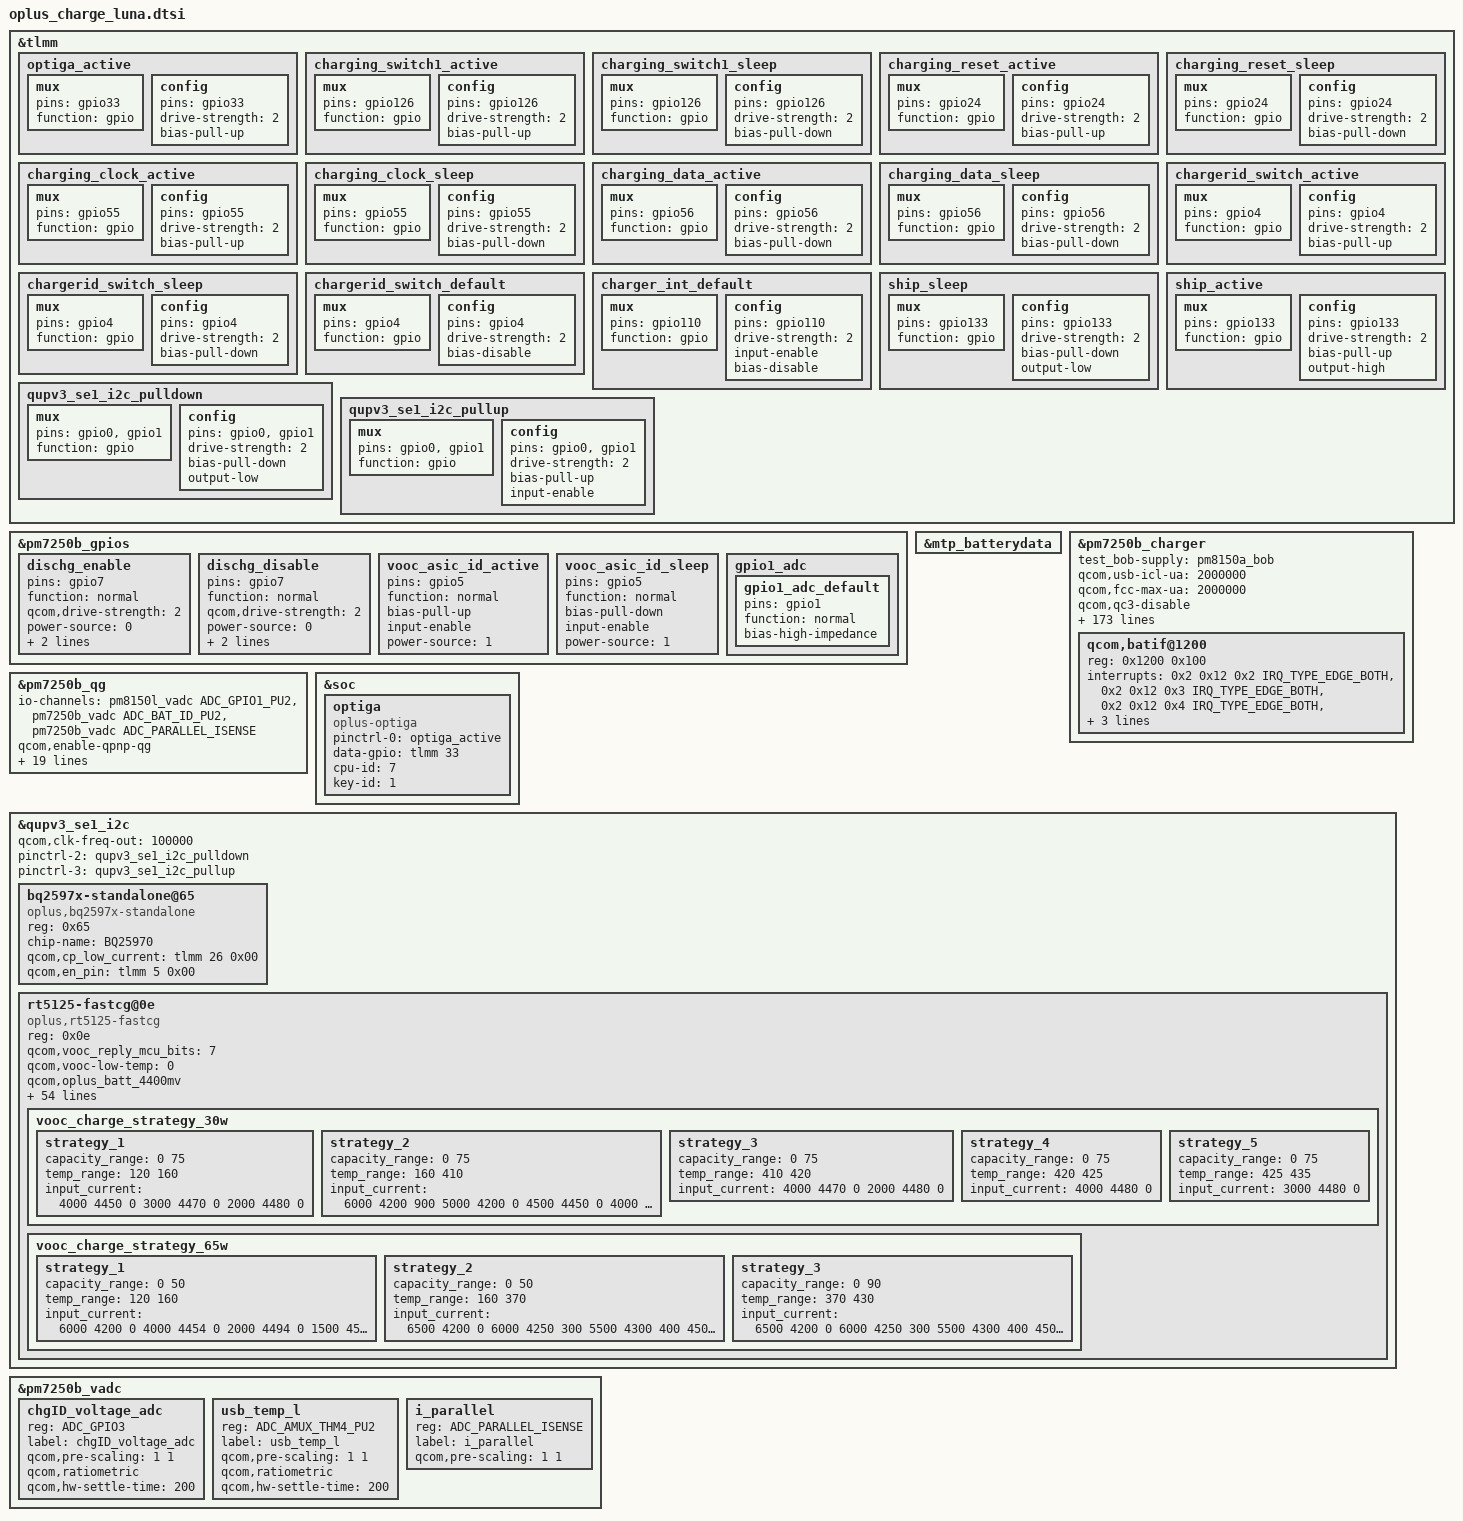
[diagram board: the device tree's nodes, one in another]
// SPDX-License-Identifier: GPL-2.0-only
/*
 * Copyright (C) 2018-2020 Oplus. All rights reserved.
 */

&tlmm {
	optiga_active: optiga_active {
				mux {
					pins = "gpio33";
					function = "gpio";
				};

				config {
					pins = "gpio33";
					drive-strength = <2>;
					bias-pull-up;
				};
	};

			charging_switch1_active: charging_switch1_active {
				mux {
					pins = "gpio126";
					function = "gpio";
				};

				config {
					pins = "gpio126";
					drive-strength = <2>;
					bias-pull-up;
				};
			};

			charging_switch1_sleep: charging_switch1_sleep {
				mux {
					pins = "gpio126";
					function = "gpio";
				};

				config {
					pins = "gpio126";
					drive-strength = <2>;
					bias-pull-down;
				};
			};

			charging_reset_active: charging_reset_active {
				mux {
					pins = "gpio24";
					function = "gpio";
				};

				config {
					pins = "gpio24";
					drive-strength = <2>;
					bias-pull-up;
				};
			};

			charging_reset_sleep: charging_reset_sleep {
				mux {
					pins = "gpio24";
					function = "gpio";
				};

				config {
					pins = "gpio24";
					drive-strength = <2>;
					bias-pull-down;
				};
			};

			charging_clock_active: charging_clock_active {
				mux {
					pins = "gpio55";
					function = "gpio";
				};

				config {
					pins = "gpio55";
					drive-strength = <2>;
					bias-pull-up;
				};
			};

			charging_clock_sleep: charging_clock_sleep {
				mux {
					pins = "gpio55";
					function = "gpio";
				};

				config {
					pins = "gpio55";
					drive-strength = <2>;
					bias-pull-down;
				};
			};

			charging_data_active: charging_data_active {
				mux {
					pins = "gpio56";
					function = "gpio";
				};

				config {
					pins = "gpio56";
					drive-strength = <2>;
					bias-pull-down;
				};
			};

			charging_data_sleep: charging_data_sleep {
				mux {
					pins = "gpio56";
					function = "gpio";
				};

				config {
					pins = "gpio56";
					drive-strength = <2>;
					bias-pull-down;
				};
			};

			chargerid_switch_active: chargerid_switch_active {
				mux {
					pins = "gpio4";
					function = "gpio";
				};

				config {
					pins = "gpio4";
					drive-strength = <2>;
					bias-pull-up;
				};
			};

			chargerid_switch_sleep: chargerid_switch_sleep {
				mux {
					pins = "gpio4";
					function = "gpio";
				};

				config {
					pins = "gpio4";
					drive-strength = <2>;
					bias-pull-down;
				};
			};

			chargerid_switch_default: chargerid_switch_default {
				mux {
					pins = "gpio4";
					function = "gpio";
				};

				config {
					pins = "gpio4";
					drive-strength = <2>;
					bias-disable; /* NO PULL */
				};
			};

			charger_int_default: charger_int_default {
				mux {
					pins = "gpio110";
					function = "gpio";
				};

				config {
					pins = "gpio110";
					drive-strength = <2>;
					input-enable;
					//bias-pull-up; /*PULL UP*/
					bias-disable;
				};
			};

			ship_sleep: ship_sleep {
				mux {
					pins = "gpio133";
					function = "gpio";
				};

				config {
					pins = "gpio133";
					drive-strength = <2>;
					bias-pull-down;
					output-low;
				};
			};

			ship_active: ship_active {
				mux {
					pins = "gpio133";
					function = "gpio";
				};

				config {
					pins = "gpio133";
					drive-strength = <2>;
					bias-pull-up;
					output-high;
				};
			};

			qupv3_se1_i2c_pulldown: qupv3_se1_i2c_pulldown {
				mux {
					pins = "gpio0", "gpio1";
					function = "gpio";
				};

				config {
					pins = "gpio0", "gpio1";
					drive-strength = <2>;
					bias-pull-down;
					output-low;
				};
			};

			qupv3_se1_i2c_pullup: qupv3_se1_i2c_pullup {
				mux {
					pins = "gpio0", "gpio1";
					function = "gpio";
				};

				config {
					pins = "gpio0", "gpio1";
					drive-strength = <2>;
					bias-pull-up;
					input-enable;
				};
			};

/*
			chg_qupv3_se2_2uart_default: chg_qupv3_se2_2uart_default {
				mux {
					pins = "gpio36", "gpio37";
					function = "gpio";
				};

				config {
					pins = "gpio36", "gpio37";
					drive-strength = <2>;
					input-enable;
					bias-pull-down;
				};
			};

			chg_qupv3_se2_2uart_sleep: chg_qupv3_se2_2uart_sleep {
				mux {
					pins = "gpio36", "gpio37";
					function = "gpio";
				};

				config {
					pins = "gpio36", "gpio37";
					drive-strength = <2>;
					input-enable;
					bias-disable;
				};
			};

			shipmode_id_active: shipmode_id_active {
				mux {
					pins = "gpio25";
					function = "gpio";
				};

				config {
					pins = "gpio25";
					drive-strength = <2>;
					input-enable;
					bias-pull-up; 
				};
			};

			shortc_active: shortc_active {
				mux {
					pins = "gpio43";
					function = "gpio";
				};

				config {
					pins = "gpio43";
					drive-strength = <2>;
					input-enable;
					bias-pull-up; 
				};
			};
*/

};

&pm7250b_gpios {
	dischg_enable: dischg_enable{
		pins = "gpio7";
		function = "normal";
		qcom,drive-strength = <2>;
		power-source = <0>;
		bias-disable;
		output-high;
	};

	dischg_disable: dischg_disable{
		pins = "gpio7";
		function = "normal";
		qcom,drive-strength = <2>;
		power-source = <0>;
		bias-disable;
		output-low;
	};

    vooc_asic_id_active: vooc_asic_id_active {
		pins = "gpio5";
		function = "normal";
		bias-pull-up;
		input-enable;
		power-source = <1>;
	};

    vooc_asic_id_sleep: vooc_asic_id_sleep {
		pins = "gpio5";
		function = "normal";
		bias-pull-down;
		input-enable;
		power-source = <1>;
	};

	gpio1_adc {
        gpio1_adc_default: gpio1_adc_default {
        pins = "gpio1"; /* GPIO 1 */
        function = "normal"; /* normal */
        bias-high-impedance; /* DISABLE GPIO1 for ADC*/
        };
    };
};

&mtp_batterydata {
	#include "oplus_battery_4500mah_100k_pm7250b_BLP857.dtsi"
	/delete-node/ qcom,ATL466271_3300mAh;
	/delete-node/ qcom,alium_860_89032_0000_3600mAh;
};

&pm7250b_charger {
			test_bob-supply = <&pm8150a_bob>;
			qcom,usb-icl-ua = <2000000>;
			qcom,fcc-max-ua = <2000000>;
			//qcom,fv-max-uv = <4373000>;
			qcom,qc3-disable;
			qcom,hvdcp-disable;
			qcom,get_mcu_voltage_enable;
			qcom,smart_charging_screenoff;
			qcom,internal_gauge_with_asic = <1>;
			//io-channels = <&pm8150b_vadc ADC_GPIO3>;
			//io-channel-names = "chgID_voltage_adc";
			qcom,otg-cl-ua = <1400000>;
			qcom,float-option = <1>;
			qcom,oplus-pps-usbpd-detection = <&pm7250b_pdphy>;

			qcom,usbtemp_batttemp_gap = <12>;

			//for oplus chg framework:
			qcom,input_current_charger_ma = <2000>;
			qcom,pd_input_current_charger_ma = <2000>;
			qcom,qc_input_current_charger_ma = <2000>;
			qcom,input_current_usb_ma = <500>;

			qcom,input_current_led_ma = <1200>;
			qcom,input_current_led_ma_high = <1200>;
			qcom,input_current_led_ma_warm = <1500>;
			qcom,input_current_led_ma_normal = <2000>;

			qcom,input_current_camera_ma = <1200>;
			qcom,input_current_cdp_ma = <1600>;
			//qcom,input_current_led_ma_overtemp = <900>;
			qcom,overtemp_bat_decidegc = <350>;
			qcom,iterm_disabled = <0>;
			sw_full_count = <25>;
			qcom,iterm_ma = <221>;
			qcom,recharge-mv = <100>;
			qcom,batt_capacity_mah = <4500>;/*typical capacity*/
			//qcom,batt_capacity_mah = <3920>; /*rated capacity*/

			qcom,removed_bat_decidegc = <190>;  /*<-19C*/

			qcom,cold_bat_decidegc = <20>;  /*-2C~0C*/
			qcom,temp_cold_vfloat_mv = <3980>;
			qcom,temp_cold_fastchg_current_ma = <314>;

			qcom,little_cold_bat_decidegc = <0>;	/*0C~5C*/
			qcom,temp_little_cold_vfloat_mv = <4435>;
			qcom,temp_little_cold_fastchg_current_ma_high = <2200>;
			qcom,temp_little_cold_fastchg_current_ma_low = <2200>;
			qcom,pd_temp_little_cold_fastchg_current_ma_high = <2594>;
			qcom,pd_temp_little_cold_fastchg_current_ma_low = <3300>;
			qcom,temp_little_cold_fastchg_current_ma = <1076>;
			qcom,qc_temp_little_cold_fastchg_current_ma_high = <2594>;
			qcom,qc_temp_little_cold_fastchg_current_ma_low = <3300>;
        
			qcom,cool_bat_decidegc = <50>;	/*5C~12C*/
			qcom,temp_cool_vfloat_mv = <4435>;
			qcom,temp_cool_fastchg_current_ma_high = <2200>;
			qcom,temp_cool_fastchg_current_ma_low = <2200>;
			qcom,qc_temp_cool_fastchg_current_ma_high = <3300>;	//2464
			qcom,qc_temp_cool_fastchg_current_ma_low = <3300>;	//1760
			qcom,pd_temp_cool_fastchg_current_ma_high = <3300>;	//2464
			qcom,pd_temp_cool_fastchg_current_ma_low = <3300>;	//1760

			qcom,little_cool_bat_decidegc = <120>;	/*12C~16C*/
			qcom,temp_little_cool_vfloat_mv = <4435>;
			qcom,temp_little_cool_fastchg_current_ma = <2200>;
			qcom,pd_temp_little_cool_fastchg_current_ma = <3300>;
			qcom,qc_temp_little_cool_fastchg_current_ma = <3300>;
	
			qcom,normal_bat_decidegc = <160>;	/*16C~44C*/
			qcom,temp_normal_fastchg_current_ma = <2200>;
			qcom,pd_temp_normal_fastchg_current_ma = <3300>;
			qcom,qc_temp_normal_fastchg_current_ma = <3300>;
			qcom,temp_normal_vfloat_mv = <4435>;

			qcom,warm_bat_decidegc = <450>;		/*45C~53C*/ /*8pin Bat Vooc project need add 3 degree C*/
			qcom,temp_warm_vfloat_mv = <4130>;
			qcom,temp_warm_fastchg_current_ma = <1152>;
			qcom,pd_temp_warm_fastchg_current_ma = <1152>;
			qcom,qc_temp_warm_fastchg_current_ma = <1152>;
			qcom,temp_warm_fastchg_current_ma_led_on = <500>;
	
			qcom,hot_bat_decidegc = <530>;

			qcom,non_standard_vfloat_mv = <3980>;
			qcom,non_standard_fastchg_current_ma = <550>;
	
			qcom,short_c_bat_cv_mv = <4330>;
			qcom,short_c_bat_vfloat_mv = <3800>;
			qcom,short_c_bat_fastchg_current_ma = <512>;

			qcom,cold_vfloat_sw_limit = <3930>;
			qcom,little_cold_vfloat_sw_limit = <4370>;
			qcom,cool_vfloat_sw_limit = <4370>;
			qcom,little_cool_vfloat_sw_limit = <4370>;
			qcom,normal_vfloat_sw_limit = <4435>;
			qcom,warm_vfloat_sw_limit = <4080>;
			qcom,non_standard_vfloat_sw_limit = <3930>;
			qcom,short_c_bat_vfloat_sw_limit = <3750>;

			qcom,max_chg_time_sec = <36000>;
			qcom,charger_hv_thr = <11000>;
			qcom,charger_recv_thr = <9700>;
			qcom,charger_lv_thr = <3400>;
			qcom,vbatt_full_thr = <4400>;
			qcom,vbatt_hv_thr = <4600>;
			qcom,vfloat_step_mv = <16>;
			qcom,non_standard_vfloat_over_sw_limit = <3980>;
			qcom,cold_vfloat_over_sw_limit = <3980>;
			qcom,little_cold_vfloat_over_sw_limit = <4440>;
			qcom,cool_vfloat_over_sw_limit = <4440>;
			qcom,little_cool_vfloat_over_sw_limit = <4440>;
			qcom,normal_vfloat_over_sw_limit = <4440>;
			qcom,warm_vfloat_over_sw_limit = <4130>;

			qcom,vbatt_power_off = <3300>;
			qcom,vbatt_soc_1 = <3410>;
			qcom,vooc_project = <3>;
			qcom,vbatt_num = <1>;
			qcom,new_ui_warning_support;
			qcom,ffc_support;
			recharge_after_full;
                        qcom,nightstandby_support;
                        qcom,vooc_enable_charger_first;

			qcom,normal_vterm_hw_inc = <18>;
			qcom,non_normal_vterm_hw_inc = <18>;

			qcom,ff1_normal_fastchg_ma = <1500>;
			qcom,ff1_warm_fastchg_ma = <1750>;	/* 35C ~ 40c */
			qcom,ff1_exit_step_ma = <100>;
			qcom,ff1_warm_exit_step_ma = <150>;
			qcom,ffc2_normal_fastchg_ma = <1500>;/*12C~35c*/
			qcom,ffc2_warm_fastchg_ma = <1750>;	/* 35C ~ 40c */
			qcom,ffc2_temp_warm_decidegc = <350>;
			qcom,ffc2_temp_high_decidegc = <400>;
			qcom,ffc2_temp_low_decidegc = <160>;
			qcom,ffc2_exit_step_ma = <150>;
			qcom,ffc2_warm_exit_step_ma = <150>;

			qcom,ffc_normal_vfloat_sw_limit = <4485>;
			qcom,ffc2_normal_vfloat_sw_limit = <4485>;
			qcom,ffc_temp_normal_vfloat_mv = <4550>;
			qcom,ffc_normal_vfloat_over_sw_limit = <4550>;

			qcom,default_iterm_ma = <221>;
			qcom,default_temp_normal_fastchg_current_ma = <2200>;
			qcom,default_normal_vfloat_sw_limit = <4385>;
			qcom,default_temp_normal_vfloat_mv = <4435>;
			qcom,default_normal_vfloat_over_sw_limit = <4440>;

			qcom,default_temp_little_cool_fastchg_current_ma = <2200>;
			qcom,default_little_cool_vfloat_sw_limit = <4385>;
			qcom,default_temp_little_cool_vfloat_mv = <4435>;
			qcom,default_little_cool_vfloat_over_sw_limit = <4445>;
			qcom,vbatt_pdqc_to_5v_thr = <4500>;
			qcom,vbatt_pdqc_to_9v_thr = <4500>;
			qcom,smart_charge_version = <1>;

			qcom,vooc_show_ui_soc_decimal;
			qcom,usbtemp_batttemp_high_gap = <14>;
			qcom,ui_soc_decimal_speedmin = <20>;//2A

			///qcom,offset_temp = <30>;
			//for control:
			//qcom,suspend_after_full;
			qcom,check_batt_full_by_sw;
			//qcom,external_gauge;
                        qcom,external_authenticate;
			qcom,fg_bcl_poll_enable;
			qcom,chg_ctrl_by_lcd;
			qcom,chg_ctrl_by_camera;
			qcom,sw_vfloat_over_protect_enable;
			qcom,lpd-disable;
			//qcom,smooth_switch;
			qcom,dual_ffc;

			qcom,chargerid_switch-gpio = <&tlmm 4 0x00>;
			qcom,ship-mode-config = <1>;
			qcom,ship-gpio = <&tlmm 133 0x00>;
			//qcom,shortc-gpio = <&tlmm 43 0x00>;
			qcom,dischg-gpio = <&pm7250b_gpios 7 0x00>;

			io-channels = <&pm7250b_vadc ADC_USB_IN_V_16>,
							<&pm7250b_vadc ADC_USB_IN_I>,
							<&pm7250b_vadc ADC_CHG_TEMP>,
							<&pm7250b_vadc ADC_GPIO3>,
							<&pm7250b_vadc ADC_AMUX_THM4_PU2>,
//
							<&pm7250b_vadc ADC_DIE_TEMP>,
							<&pm7250b_vadc ADC_AMUX_THM3_PU2>,
							<&pm7250b_vadc ADC_SBUx>,
							<&pm7250b_vadc ADC_VPH_PWR>,
							<&pm8150l_vadc ADC_AMUX_THM2_PU2>;
			io-channel-names = "usb_in_voltage",
								"usb_in_current",
								"chg_temp",
								"chgID_voltage_adc",
								"usb_temp_l",
//
								"die_temp",
								"usb_temp_r",
//#else
								//"conn_temp",
//#endif
								"sbux_res",
								"vph_voltage",
								"skin_temp";

			pinctrl-names = "chargerid_switch_active", "chargerid_switch_sleep", "chargerid_switch_default",
							"ship_active", "ship_sleep",
							"dischg_enable", "dischg_disable",
							"gpio1_adc_default";

			pinctrl-0 = <&chargerid_switch_active>;
			pinctrl-1 = <&chargerid_switch_sleep>;
			pinctrl-2 = <&chargerid_switch_default>;
			pinctrl-3 = <&ship_active>;
			pinctrl-4 = <&ship_sleep>;
			pinctrl-5 = <&dischg_enable>;
			pinctrl-6 = <&dischg_disable>;
			pinctrl-7 = <&gpio1_adc_default>;
};

&pm7250b_qg {
	status = "ok";
	io-channels = <&pm8150l_vadc ADC_GPIO1_PU2>,
		      <&pm7250b_vadc ADC_BAT_ID_PU2>,
			  <&pm7250b_vadc ADC_PARALLEL_ISENSE>;
	io-channel-names = "batt-therm_30k",
			   "batt-id",
			   "parallel_isense";
	qcom,enable-qpnp-qg;
	qcom,qg-ext-sns;
	qcom,oplus_small_board_temp;
	qcom,battery-data = <&mtp_batterydata>;
	qcom,qg-iterm-ma = <260>;
	qcom,rbat-conn-mohm = <0>;
	qcom,qg-fast-chg-config;
	//qcom,hold-soc-while-full;
	qcom,linearize-soc;
	qcom,cl-feedback-on;
	qcom,tcss-enable;
	qcom,fvss-enable;
	qcom,fvss-vbatt-mv = <3300>;
	qcom,bass-enable;
	qcom,s3-entry-ibat-ua = <40000>;
	qcom,s3-exit-ibat-ua = <40000>;
	qcom,adc-compensation-enable;
	qcom,compensation-impedance = <11>;
        qcom,asic-with-internal-gauge;
        qcom,ignore-shutdown-soc-secs = <86400>;
        qcom,shutdown-temp-diff = <250>;
};

&soc {
	optiga {
		compatible = "oplus-optiga";
		status = "ok";
		pinctrl-names = "optiga_active";
		pinctrl-0 = <&optiga_active>;
		data-gpio = <&tlmm 33 0x00>;
		cpu-id = <7>;
		key-id = <1>;
	};
};

&qupv3_se1_i2c {
	status = "okay";

	qcom,clk-freq-out = <100000>;
	pinctrl-names = "default", "sleep", "pulldown", "pullup";
	pinctrl-2 = <&qupv3_se1_i2c_pulldown>;
	pinctrl-3 = <&qupv3_se1_i2c_pullup>;
//#endif //OPLUS_FEATURE_CHG_BASIC
/*
	oplus_short-ic@58 {
		status = "okay";
		compatible = "oplus,oplus_short-ic";
		reg = <0x58>;
	};
*/
	bq2597x-standalone@65 {
		status = "okay";
		compatible = "oplus,bq2597x-standalone";
		reg = <0x65>;
		chip-name = "BQ25970";
		qcom,cp_low_current = <&tlmm 26 0x00>;
		qcom,en_pin = <&tlmm 5 0x00>;
	};
	
	rt5125-fastcg@0e{
		status = "okay";
		compatible = "oplus,rt5125-fastcg";
		reg = <0x0e>;
		qcom,vooc_reply_mcu_bits = <7>;
		qcom,vooc-low-temp = <0>;
		qcom,oplus_batt_4400mv;
		qcom,vooc-high-soc = <90>;
		qcom,vooc-high-temp = <430>;
		qcom,vooc_batt_over_high_temp = <440>;

		qcom,vooc_cool_bat_volt = <3650>;
		qcom,vooc_little_cool_bat_volt = <3550>;
		qcom,vooc_normal_bat_volt = <3450>;
		qcom,vooc_warm_bat_volt = <3350>;

		qcom,vooc_cool_bat_suspend_volt = <3650>;
		qcom,vooc_little_cool_bat_suspend_volt = <3550>;
		qcom,vooc_normal_bat_suspend_volt = <3450>;
		qcom,vooc_warm_bat_suspend_volt = <3350>;

		qcom,vooc_fw_update_newmethod;
		qcom,vooc-fw-type = <8>;
                #include "fastchg_fw/fw_svooc_10v5a5v6a_4.45v_2065c_rt5125_0x0020_4_3A.dtsi"
		qcom,support-single-batt-svooc;
		qcom,vooc_is_platform_gauge;
		qcom,vooc_multistep_adjust_current_support;
		qcom,vooc_multistep_initial_batt_temp = <1000>;
		qcom,vooc_strategy_normal_current = <0xb>;

		qcom,vooc_strategy1_batt_high_temp0 = <385>;
		qcom,vooc_strategy1_batt_high_temp1 = <395>;
		qcom,vooc_strategy1_batt_high_temp2 = <420>;
		qcom,vooc_strategy1_batt_low_temp2 = <410>;
		qcom,vooc_strategy1_batt_low_temp1 = <385>;
		qcom,vooc_strategy1_batt_low_temp0 = <375>;

		qcom,vooc_strategy1_high_current0 = <0x09>;
		qcom,vooc_strategy1_high_current1 = <0x07>;
		qcom,vooc_strategy1_high_current2 = <0x05>;
		qcom,vooc_strategy1_low_current2 = <0x07>;
		qcom,vooc_strategy1_low_current1 = <0x09>;
		qcom,vooc_strategy1_low_current0 = <0xb>;
/*
		qcom,vooc_strategy1_batt_high_temp0 = <710>;
		qcom,vooc_strategy1_batt_high_temp1 = <720>;
		qcom,vooc_strategy1_batt_high_temp2 = <735>;
		qcom,vooc_strategy1_batt_low_temp2 = <715>;
		qcom,vooc_strategy1_batt_low_temp1 = <700>;
		qcom,vooc_strategy1_batt_low_temp0 = <690>;

		qcom,vooc_strategy1_high_current0 = <0x03>;
		qcom,vooc_strategy1_high_current1 = <0x02>;
		qcom,vooc_strategy1_high_current2 = <0x02>;
		qcom,vooc_strategy1_low_current2 = <0x02>;
		qcom,vooc_strategy1_low_current1 = <0x02>;
		qcom,vooc_strategy1_low_current0 = <0x03>;
*/
		qcom,vooc_current_lvl = <2000
									2000
									2000
									3000
									4000
									5000
									6000
									7000
									8000
									9000
									10000>;

		pinctrl-names = "switch1_act_switch2_act", "switch1_sleep_switch2_sleep",
						"switch1_act_switch3_act", "switch1_sleep_switch3_sleep",
						"switch1_act_switch2_sleep", "switch1_sleep_switch2_act",
						"clock_active","clock_sleep",
						"data_active","data_sleep",
						"reset_active","reset_sleep",
						"vooc_asic_id_active","vooc_asic_id_sleep";
		pinctrl-0 = <&charging_switch1_active>;
		pinctrl-1 = <&charging_switch1_sleep>;
		pinctrl-2 = <&charging_switch1_active>;
		pinctrl-3 = <&charging_switch1_sleep>;
		pinctrl-4 = <&charging_switch1_active>;
		pinctrl-5 = <&charging_switch1_sleep>;
		pinctrl-6 = <&charging_clock_active>;
		pinctrl-7 = <&charging_clock_sleep>;
		pinctrl-8 = <&charging_data_active>;
		pinctrl-9 = <&charging_data_sleep>;
		pinctrl-10 = <&charging_reset_active>;
		pinctrl-11 = <&charging_reset_sleep>;
		pinctrl-12 = <&vooc_asic_id_active>;
		pinctrl-13 = <&vooc_asic_id_sleep>;

		qcom,charging_switch1-gpio = <&tlmm 126 0x00>;
		qcom,charging_switch1_ctr1-gpio 	= <&tlmm 132 0x00>;
		//qcom,charging_switch2-gpio 		= <&tlmm 113 0x00>;
		//qcom,charging_switch3-gpio 		= <&tlmm 38 0x00>;

		qcom,charging_reset-gpio 			= <&tlmm 24 0x00>;
		qcom,charging_clock-gpio 			= <&tlmm 55 0x00>;
		qcom,charging_data-gpio 			= <&tlmm 56 0x00>;
		qcom,vooc_asic_id-gpio				= <&pm7250b_gpios 5 0x00>;

                qcom,vooc-max-input-volt-support = <10000>;     //10V
                qcom,vooc-max-input-current-support = <6500>;   //6A
                vooc_charge_strategy_30w {
                        strategy_1 {
                                capacity_range = <0 75>;
                                temp_range = <120 160>;
                                input_current = <4000 4450 0
                                                3000 4470 0
                                                2000 4480 0>;
                        };
                        strategy_2 {
                                capacity_range = <0 75>;
                                temp_range = <160 410>;
                                input_current = <6000 4200 900
                                                5000 4200 0
                                                4500 4450 0
                                                4000 4450 0
                                                3000 4470 0
                                                2000 4480 0>;
                        };
                        strategy_3 {
                                capacity_range = <0 75>;
                                temp_range = <410 420>;
                                input_current = <4000 4470 0
                                                2000 4480 0>;
                        };
                        strategy_4 {
                                capacity_range = <0 75>;
                                temp_range = <420 425>;
                                input_current = <4000 4480 0>;
                        };
                        strategy_5 {
                                capacity_range = <0 75>;
                                temp_range = <425 435>;
                                input_current = <3000 4480 0>;
                        };
                };

                vooc_charge_strategy_65w {
                        strategy_1 {
                                capacity_range = <0 50>;
                                temp_range = <120 160>;
                                input_current = <6000 4200 0
                                                4000 4454 0
                                                2000 4494 0
                                                1500 4500 0>;
                        };
                        strategy_2 {
                                capacity_range = <0 50>;
                                temp_range = <160 370>;
                                input_current = <6500 4200 0
                                                6000 4250 300
                                                5500 4300 400
                                                4500 4454 780
                                                3500 4454 0
                                                2000 4494 0
                                                1500 4500 0>;
                        };
                        strategy_3 {
                                capacity_range = <0 90>;
                                temp_range = <370 430>;
                                input_current = <6500 4200 0
                                                6000 4250 300
                                                5500 4300 400
                                                4500 4454 780
                                                3500 4454 0
                                                2000 4494 0
                                                1600 4500 0>;
                        };
                };

	};

};
&pm7250b_vadc {
	chgID_voltage_adc {
		reg = <ADC_GPIO3>;
		label = "chgID_voltage_adc";
		qcom,pre-scaling = <1 1>;
		qcom,ratiometric;
		qcom,hw-settle-time = <200>;
	};
	usb_temp_l {
		reg = <ADC_AMUX_THM4_PU2>;
		label = "usb_temp_l";
		qcom,pre-scaling = <1 1>;
		qcom,ratiometric;
		qcom,hw-settle-time = <200>;
	};
	i_parallel {
		reg = <ADC_PARALLEL_ISENSE>;
		label = "i_parallel";
		qcom,pre-scaling = <1 1>;
	};
};

&pm7250b_charger {
	qcom,batif@1200 {
			reg = <0x1200 0x100>;
			interrupts =
					<0x2 0x12 0x2 IRQ_TYPE_EDGE_BOTH>,
					<0x2 0x12 0x3 IRQ_TYPE_EDGE_BOTH>,
					<0x2 0x12 0x4 IRQ_TYPE_EDGE_BOTH>,
					<0x2 0x12 0x5 IRQ_TYPE_EDGE_BOTH>,
					<0x2 0x12 0x6 IRQ_TYPE_EDGE_BOTH>,
					<0x2 0x12 0x7 IRQ_TYPE_EDGE_BOTH>;
			interrupt-names = "bat-ov",
							  "bat-low",
							  "bat-therm-or-id-missing",
							  "bat-terminal-missing",
							  "buck-oc",
							  "vph-ov";
	};
};
